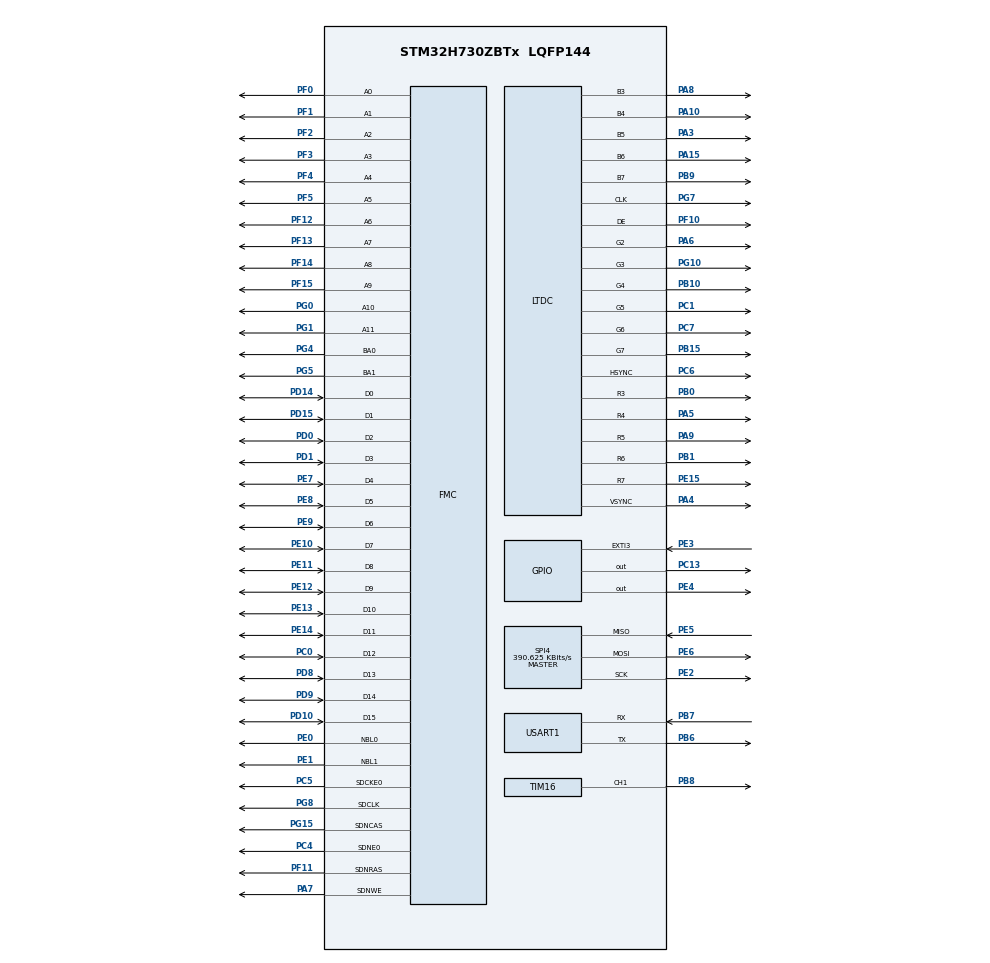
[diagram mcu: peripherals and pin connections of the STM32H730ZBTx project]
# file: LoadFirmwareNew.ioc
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CORTEX_M7.AccessPermission_S-Cortex_Memory_Protection_Unit_Region2_Settings_S=MPU_REGION_FULL_ACCESS
CORTEX_M7.AccessPermission_S-Cortex_Memory_Protection_Unit_Region3_Settings_S=MPU_REGION_FULL_ACCESS
CORTEX_M7.AccessPermission_S-Cortex_Memory_Protection_Unit_Region4_Settings_S=MPU_REGION_FULL_ACCESS
CORTEX_M7.AccessPermission_Spec=MPU_REGION_FULL_ACCESS
CORTEX_M7.BaseAddress_S-Cortex_Memory_Protection_Unit_Region2_Settings_S=0x38000000
CORTEX_M7.BaseAddress_S-Cortex_Memory_Protection_Unit_Region3_Settings_S=0x08000000
CORTEX_M7.BaseAddress_S-Cortex_Memory_Protection_Unit_Region4_Settings_S=0x90000000
CORTEX_M7.BaseAddress_Spec=0xC0000000
CORTEX_M7.CPU_DCache=Enabled
CORTEX_M7.CPU_ICache=Enabled
CORTEX_M7.DisableExec_S-Cortex_Memory_Protection_Unit_Region2_Settings_S=MPU_INSTRUCTION_ACCESS_DISABLE
CORTEX_M7.Enable_S-Cortex_Memory_Protection_Unit_Region1_Settings_S=__NULL
CORTEX_M7.Enable_S-Cortex_Memory_Protection_Unit_Region2_Settings_S=MPU_REGION_ENABLE
CORTEX_M7.Enable_S-Cortex_Memory_Protection_Unit_Region3_Settings_S=MPU_REGION_ENABLE
CORTEX_M7.Enable_S-Cortex_Memory_Protection_Unit_Region4_Settings_S=MPU_REGION_ENABLE
CORTEX_M7.IsBufferable_S-Cortex_Memory_Protection_Unit_Region2_Settings_S=MPU_ACCESS_BUFFERABLE
CORTEX_M7.IsBufferable_S-Cortex_Memory_Protection_Unit_Region4_Settings_S=MPU_ACCESS_NOT_BUFFERABLE
CORTEX_M7.IsBufferable_Spec=MPU_ACCESS_BUFFERABLE
CORTEX_M7.IsCacheable_S-Cortex_Memory_Protection_Unit_Region2_Settings_S=MPU_ACCESS_CACHEABLE
CORTEX_M7.IsCacheable_S-Cortex_Memory_Protection_Unit_Region3_Settings_S=MPU_ACCESS_CACHEABLE
CORTEX_M7.IsCacheable_S-Cortex_Memory_Protection_Unit_Region4_Settings_S=MPU_ACCESS_CACHEABLE
CORTEX_M7.IsCacheable_Spec=MPU_ACCESS_CACHEABLE
CORTEX_M7.IsShareable_S-Cortex_Memory_Protection_Unit_Region2_Settings_S=MPU_ACCESS_SHAREABLE
CORTEX_M7.IsShareable_S-Cortex_Memory_Protection_Unit_Region3_Settings_S=MPU_ACCESS_NOT_SHAREABLE
CORTEX_M7.IsShareable_S-Cortex_Memory_Protection_Unit_Region4_Settings_S=MPU_ACCESS_NOT_SHAREABLE
CORTEX_M7.IsShareable_Spec=MPU_ACCESS_SHAREABLE
CORTEX_M7.Size_S-Cortex_Memory_Protection_Unit_Region2_Settings_S=MPU_REGION_SIZE_16KB
CORTEX_M7.Size_S-Cortex_Memory_Protection_Unit_Region3_Settings_S=MPU_REGION_SIZE_128KB
CORTEX_M7.Size_S-Cortex_Memory_Protection_Unit_Region4_Settings_S=MPU_REGION_SIZE_16MB
CORTEX_M7.Size_Spec=MPU_REGION_SIZE_8MB
CORTEX_M7.SubRegionDisable_Spec=0x00
CORTEX_M7.default_mode_Activation=1
DMA2D.ColorMode=DMA2D_OUTPUT_RGB565
DMA2D.Mode=DMA2D_R2M
Dma.Request0=USART1_RX
Dma.Request1=USART1_TX
Dma.USART1_RX.0.Direction=DMA_PERIPH_TO_MEMORY
Dma.USART1_RX.0.EventEnable=DISABLE
Dma.USART1_RX.0.FIFOMode=DMA_FIFOMODE_DISABLE
Dma.USART1_RX.0.Instance=DMA1_Stream0
Dma.USART1_RX.0.MemDataAlignment=DMA_MDATAALIGN_BYTE
Dma.USART1_RX.0.MemInc=DMA_MINC_ENABLE
Dma.USART1_RX.0.Mode=DMA_CIRCULAR
Dma.USART1_RX.0.PeriphDataAlignment=DMA_PDATAALIGN_BYTE
Dma.USART1_RX.0.PeriphInc=DMA_PINC_DISABLE
Dma.USART1_RX.0.Polarity=HAL_DMAMUX_REQ_GEN_RISING
Dma.USART1_RX.0.Priority=DMA_PRIORITY_LOW
Dma.USART1_RX.0.RequestNumber=1
Dma.USART1_RX.0.SignalID=NONE
Dma.USART1_RX.0.SyncEnable=DISABLE
Dma.USART1_RX.0.SyncPolarity=HAL_DMAMUX_SYNC_NO_EVENT
Dma.USART1_RX.0.SyncRequestNumber=1
Dma.USART1_RX.0.SyncSignalID=NONE
Dma.USART1_TX.1.Direction=DMA_MEMORY_TO_PERIPH
Dma.USART1_TX.1.EventEnable=DISABLE
Dma.USART1_TX.1.FIFOMode=DMA_FIFOMODE_DISABLE
Dma.USART1_TX.1.Instance=DMA1_Stream1
Dma.USART1_TX.1.MemDataAlignment=DMA_MDATAALIGN_BYTE
Dma.USART1_TX.1.MemInc=DMA_MINC_ENABLE
Dma.USART1_TX.1.Mode=DMA_NORMAL
Dma.USART1_TX.1.PeriphDataAlignment=DMA_PDATAALIGN_BYTE
Dma.USART1_TX.1.PeriphInc=DMA_PINC_DISABLE
Dma.USART1_TX.1.Polarity=HAL_DMAMUX_REQ_GEN_RISING
Dma.USART1_TX.1.Priority=DMA_PRIORITY_LOW
Dma.USART1_TX.1.RequestNumber=1
Dma.USART1_TX.1.SignalID=NONE
Dma.USART1_TX.1.SyncEnable=DISABLE
Dma.USART1_TX.1.SyncPolarity=HAL_DMAMUX_SYNC_NO_EVENT
Dma.USART1_TX.1.SyncRequestNumber=1
Dma.USART1_TX.1.SyncSignalID=NONE
FMC.CASLatency1=FMC_SDRAM_CAS_LATENCY_2
FMC.ExitSelfRefreshDelay1=7
FMC.LoadToActiveDelay1=2
FMC.RCDDelay1=2
FMC.RPDelay1=2
FMC.RowCycleDelay1=6
FMC.SDClockPeriod1=FMC_SDRAM_CLOCK_PERIOD_2
FMC.SelfRefreshTime1=4
FMC.WriteRecoveryTime1=2
LTDC.ActiveW=800
LTDC.Alpha_L0=0xFF
LTDC.FBStartAdress_L0=0xC0000000
LTDC.FBStartAdress_L1=0xC0100000
LTDC.HBP=45
LTDC.HFP=212
LTDC.HSync=2
LTDC.ImageHeight_L0=480
LTDC.ImageHeight_L1=480
LTDC.ImageWidth_L0=800
LTDC.Layers=0
LTDC.PixelFormat_L0=LTDC_PIXEL_FORMAT_RGB565
LTDC.VBP=21
LTDC.VFP=21
LTDC.VSync=2
LTDC.WindowX1_L0=800
LTDC.WindowY1_L0=480
Mcu.Family=STM32H7
Mcu.Name=STM32H730ZBTx
Mcu.Package=LQFP144
NVIC.DMA1_Stream0_IRQn=true\:0\:0\:false\:false\:true\:false\:true\:true
NVIC.DMA1_Stream1_IRQn=true\:0\:0\:false\:false\:true\:false\:true\:true
NVIC.EXTI3_IRQn=true\:0\:0\:false\:false\:true\:true\:true\:true
NVIC.LTDC_ER_IRQn=true\:0\:0\:false\:false\:true\:true\:true\:true
NVIC.LTDC_IRQn=true\:0\:0\:false\:false\:true\:true\:true\:true
NVIC.PriorityGroup=NVIC_PRIORITYGROUP_4
NVIC.USART1_IRQn=true\:0\:0\:false\:false\:true\:true\:true\:true
PA10.GPIO_Speed=GPIO_SPEED_FREQ_VERY_HIGH
PA10.Mode=RGB565
PA10.Signal=LTDC_B4
PA15(JTDI).GPIO_Speed=GPIO_SPEED_FREQ_VERY_HIGH
PA15(JTDI).Mode=RGB565
PA15(JTDI).Signal=LTDC_B6
PA3.GPIO_Speed=GPIO_SPEED_FREQ_VERY_HIGH
PA3.Mode=RGB565
PA3.Signal=LTDC_B5
PA4.GPIO_Speed=GPIO_SPEED_FREQ_VERY_HIGH
PA4.Mode=RGB565
PA4.Signal=LTDC_VSYNC
PA5.GPIO_Speed=GPIO_SPEED_FREQ_VERY_HIGH
PA5.Mode=RGB565
PA5.Signal=LTDC_R4
PA6.GPIO_Speed=GPIO_SPEED_FREQ_VERY_HIGH
PA6.Mode=RGB565
PA6.Signal=LTDC_G2
PA7.Signal=FMC_SDNWE
PA8.GPIO_Speed=GPIO_SPEED_FREQ_VERY_HIGH
PA8.Mode=RGB565
PA8.Signal=LTDC_B3
PA9.GPIO_Speed=GPIO_SPEED_FREQ_VERY_HIGH
PA9.Mode=RGB565
PA9.Signal=LTDC_R5
PB0.GPIO_Speed=GPIO_SPEED_FREQ_VERY_HIGH
PB0.Mode=RGB565
PB0.Signal=LTDC_R3
PB1.GPIO_Speed=GPIO_SPEED_FREQ_VERY_HIGH
PB1.Mode=RGB565
PB1.Signal=LTDC_R6
PB10.GPIO_Speed=GPIO_SPEED_FREQ_VERY_HIGH
PB10.Mode=RGB565
PB10.Signal=LTDC_G4
PB15.GPIO_Speed=GPIO_SPEED_FREQ_VERY_HIGH
PB15.Mode=RGB565
PB15.Signal=LTDC_G7
PB6.Mode=Asynchronous
PB6.Signal=USART1_TX
PB7.Mode=Asynchronous
PB7.Signal=USART1_RX
PB8.Signal=S_TIM16_CH1
PB9.GPIO_Speed=GPIO_SPEED_FREQ_VERY_HIGH
PB9.Mode=RGB565
PB9.Signal=LTDC_B7
PC0.Signal=FMC_D12_DA12
PC1.GPIO_Speed=GPIO_SPEED_FREQ_VERY_HIGH
PC1.Mode=RGB565
PC1.Signal=LTDC_G5
PC13.Signal=GPIO_Output
PC4.Mode=SdramChipSelect1_1
PC4.Signal=FMC_SDNE0
PC5.Mode=SdramChipSelect1_1
PC5.Signal=FMC_SDCKE0
PC6.GPIO_Speed=GPIO_SPEED_FREQ_VERY_HIGH
PC6.Mode=RGB565
PC6.Signal=LTDC_HSYNC
PC7.GPIO_Speed=GPIO_SPEED_FREQ_VERY_HIGH
PC7.Mode=RGB565
PC7.Signal=LTDC_G6
PD0.Signal=FMC_D2_DA2
PD1.Signal=FMC_D3_DA3
PD10.Signal=FMC_D15_DA15
PD14.Signal=FMC_D0_DA0
PD15.Signal=FMC_D1_DA1
PD8.Signal=FMC_D13_DA13
PD9.Signal=FMC_D14_DA14
PE0.Signal=FMC_NBL0
PE1.Signal=FMC_NBL1
PE10.Signal=FMC_D7_DA7
PE11.Signal=FMC_D8_DA8
PE12.Signal=FMC_D9_DA9
PE13.Signal=FMC_D10_DA10
PE14.Signal=FMC_D11_DA11
PE15.GPIO_Speed=GPIO_SPEED_FREQ_VERY_HIGH
PE15.Mode=RGB565
PE15.Signal=LTDC_R7
PE2.GPIO_Speed=GPIO_SPEED_FREQ_LOW
PE2.Mode=Full_Duplex_Master
PE2.Signal=SPI4_SCK
PE3.GPIO_ModeDefaultEXTI=GPIO_MODE_IT_RISING
PE3.Signal=GPXTI3
PE4.GPIO_Speed=GPIO_SPEED_FREQ_LOW
PE4.Signal=GPIO_Output
PE5.GPIO_Speed=GPIO_SPEED_FREQ_LOW
PE5.Mode=Full_Duplex_Master
PE5.Signal=SPI4_MISO
PE6.GPIO_Speed=GPIO_SPEED_FREQ_LOW
PE6.Mode=Full_Duplex_Master
PE6.Signal=SPI4_MOSI
PE7.Signal=FMC_D4_DA4
PE8.Signal=FMC_D5_DA5
PE9.Signal=FMC_D6_DA6
PF0.Signal=FMC_A0
PF1.Signal=FMC_A1
PF10.GPIO_Speed=GPIO_SPEED_FREQ_VERY_HIGH
PF10.Mode=RGB565
PF10.Signal=LTDC_DE
PF11.Signal=FMC_SDNRAS
PF12.Signal=FMC_A6
PF13.Signal=FMC_A7
PF14.Signal=FMC_A8
PF15.Signal=FMC_A9
PF2.Signal=FMC_A2
PF3.Signal=FMC_A3
PF4.Signal=FMC_A4
PF5.Signal=FMC_A5
PG0.Signal=FMC_A10
PG1.Signal=FMC_A11
PG10.GPIO_Speed=GPIO_SPEED_FREQ_VERY_HIGH
PG10.Mode=RGB565
PG10.Signal=LTDC_G3
PG15.Signal=FMC_SDNCAS
PG4.Signal=FMC_A14_BA0
PG5.Signal=FMC_A15_BA1
PG7.GPIO_Speed=GPIO_SPEED_FREQ_VERY_HIGH
PG7.Mode=RGB565
PG7.Signal=LTDC_CLK
PG8.Signal=FMC_SDCLK
PH0-OSC_IN.Mode=HSE-External-Oscillator
PH0-OSC_IN.Signal=RCC_OSC_IN
PH1-OSC_OUT.Mode=HSE-External-Oscillator
PH1-OSC_OUT.Signal=RCC_OSC_OUT
ProjectManager.HeapSize=0x200
ProjectManager.StackSize=0x400
ProjectManager.TargetToolchain=STM32CubeIDE
RCC.ADCFreq_Value=200000000
RCC.APB1Freq_Value=100000000
RCC.APB2Freq_Value=100000000
RCC.APB3Freq_Value=100000000
RCC.APB4Freq_Value=100000000
RCC.CortexFreq_Value=400000000
RCC.D1PPRE=RCC_APB3_DIV2
RCC.D2PPRE1=RCC_APB1_DIV2
RCC.D2PPRE2=RCC_APB2_DIV2
RCC.D3PPRE=RCC_APB4_DIV2
RCC.DIVM1=2
RCC.DIVM2=10
RCC.DIVM3=1
RCC.DIVN1=32
RCC.DIVN2=160
RCC.DIVN3=4
RCC.DIVP1=1
RCC.DIVQ1=1
RCC.DIVQ2=1
RCC.DIVQ3=1
RCC.DIVR3=5
RCC.HCLKFreq_Value=200000000
RCC.HPRE=RCC_HCLK_DIV2
RCC.PLL3FRACN=0
RCC.PLLFRACN=0
RCC.PLLSourceVirtual=RCC_PLLSOURCE_HSE
RCC.SYSCLKFreq_VALUE=400000000
RCC.SYSCLKSource=RCC_SYSCLKSOURCE_PLLCLK
RCC.USBFreq_Value=400000000
SH.FMC_A0.0=FMC_A0,12b-sda1
SH.FMC_A1.0=FMC_A1,12b-sda1
SH.FMC_A10.0=FMC_A10,12b-sda1
SH.FMC_A11.0=FMC_A11,12b-sda1
SH.FMC_A14_BA0.0=FMC_BA0,FourSdramBanks1
SH.FMC_A15_BA1.0=FMC_BA1,FourSdramBanks1
SH.FMC_A2.0=FMC_A2,12b-sda1
SH.FMC_A3.0=FMC_A3,12b-sda1
SH.FMC_A4.0=FMC_A4,12b-sda1
SH.FMC_A5.0=FMC_A5,12b-sda1
SH.FMC_A6.0=FMC_A6,12b-sda1
SH.FMC_A7.0=FMC_A7,12b-sda1
SH.FMC_A8.0=FMC_A8,12b-sda1
SH.FMC_A9.0=FMC_A9,12b-sda1
SH.FMC_D0_DA0.0=FMC_D0,sd-16b-d1
SH.FMC_D10_DA10.0=FMC_D10,sd-16b-d1
SH.FMC_D11_DA11.0=FMC_D11,sd-16b-d1
SH.FMC_D12_DA12.0=FMC_D12,sd-16b-d1
SH.FMC_D13_DA13.0=FMC_D13,sd-16b-d1
SH.FMC_D14_DA14.0=FMC_D14,sd-16b-d1
SH.FMC_D15_DA15.0=FMC_D15,sd-16b-d1
SH.FMC_D1_DA1.0=FMC_D1,sd-16b-d1
SH.FMC_D2_DA2.0=FMC_D2,sd-16b-d1
SH.FMC_D3_DA3.0=FMC_D3,sd-16b-d1
SH.FMC_D4_DA4.0=FMC_D4,sd-16b-d1
SH.FMC_D5_DA5.0=FMC_D5,sd-16b-d1
SH.FMC_D6_DA6.0=FMC_D6,sd-16b-d1
SH.FMC_D7_DA7.0=FMC_D7,sd-16b-d1
SH.FMC_D8_DA8.0=FMC_D8,sd-16b-d1
SH.FMC_D9_DA9.0=FMC_D9,sd-16b-d1
SH.FMC_NBL0.0=FMC_NBL0,Sd2ByteEnable1
SH.FMC_NBL1.0=FMC_NBL1,Sd2ByteEnable1
SH.FMC_SDCLK.0=FMC_SDCLK,12b-sda1
SH.FMC_SDNCAS.0=FMC_SDNCAS,12b-sda1
SH.FMC_SDNRAS.0=FMC_SDNRAS,12b-sda1
SH.FMC_SDNWE.0=FMC_SDNWE,12b-sda1
SH.S_TIM16_CH1.0=TIM16_CH1,PWM Generation1 CH1
SPI4.BaudRatePrescaler=SPI_BAUDRATEPRESCALER_256
SPI4.CalculateBaudRate=390.625 KBits/s
SPI4.DataSize=SPI_DATASIZE_8BIT
SPI4.Direction=SPI_DIRECTION_2LINES
SPI4.Mode=SPI_MODE_MASTER
SPI4.VirtualType=VM_MASTER
STMicroelectronics.X-CUBE-TOUCHGFX.4.24.1.ApplicationCcGraphicsJjApplication=TouchGFXOoGenerator
STMicroelectronics.X-CUBE-TOUCHGFX.4.24.1.tgfx_address1=0xC0000000
STMicroelectronics.X-CUBE-TOUCHGFX.4.24.1.tgfx_address2=0xC0100000
STMicroelectronics.X-CUBE-TOUCHGFX.4.24.1.tgfx_buffering_strategy=Double
STMicroelectronics.X-CUBE-TOUCHGFX.4.24.1.tgfx_display_interface=disp_ltdc
STMicroelectronics.X-CUBE-TOUCHGFX.4.24.1.tgfx_hardware_accelerator=dma_2d
STMicroelectronics.X-CUBE-TOUCHGFX.4.24.1.tgfx_location=By Address
STMicroelectronics.X-CUBE-TOUCHGFX.4.24.1.tgfx_vector_rendering=Software
STMicroelectronics.X-CUBE-TOUCHGFX.4.24.1.tgfx_video=Software
STMicroelectronics.X-CUBE-TOUCHGFX.4.24.1.tgfx_video_height=480
STMicroelectronics.X-CUBE-TOUCHGFX.4.24.1.tgfx_video_width=800
STMicroelectronics.X-CUBE-TOUCHGFX.4.24.1.tgfx_vsync=vsync_ltdc
STMicroelectronics.X-CUBE-TOUCHGFX.4.24.1_IsPackSelfContextualization=true
TIM16.Channel=TIM_CHANNEL_1
TIM16.Period=100
TIM16.Prescaler=10000
TIM16.Pulse=100
TIM6.Period=50000 - 1
TIM6.Prescaler=55000 - 1
USART1.VirtualMode-Asynchronous=VM_ASYNC
VP_CRC_VS_CRC.Mode=CRC_Activate
VP_DMA2D_VS_DMA2D.Mode=DMA2D_Activate
VP_LIBJPEG_VS_JPEGLIB.Mode=Enabled
VP_MEMORYMAP_VS_MEMORYMAP.Mode=CurAppReg
VP_STMicroelectronics.X-CUBE-TOUCHGFX_VS_GraphicsJjApplication_4.24.1.Mode=GraphicsJjApplication
VP_TIM16_VS_ClockSourceINT.Mode=Enable_Timer
VP_TIM6_VS_ClockSourceINT.Mode=Enable_Timer
board=custom

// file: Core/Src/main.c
/* USER CODE BEGIN Header */
/**
  ******************************************************************************
  * @file           : main.c
  * @brief          : Main program body
  ******************************************************************************
  * @attention
  *
  * Copyright (c) 2024 STMicroelectronics.
  * All rights reserved.
  *
  * This software is licensed under terms that can be found in the LICENSE file
  * in the root directory of this software component.
  * If no LICENSE file comes with this software, it is provided AS-IS.
  *
  ******************************************************************************
  */
/* USER CODE END Header */
#include "main.h"
#include "crc.h"
#include "dma.h"
#include "dma2d.h"
#include "libjpeg.h"
#include "ltdc.h"
#include "memorymap.h"
#include "spi.h"
#include "tim.h"
#include "usart.h"
#include "gpio.h"
#include "fmc.h"
#include "app_touchgfx.h"

void SystemClock_Config(void);
static void MPU_Config(void);

int main(void)
{

  /* MPU Configuration--------------------------------------------------------*/
  MPU_Config();

  /* Enable the CPU Cache */

  /* Enable I-Cache---------------------------------------------------------*/
  SCB_EnableICache();

  /* Enable D-Cache---------------------------------------------------------*/
  SCB_EnableDCache();

  /* MCU Configuration--------------------------------------------------------*/

  /* Reset of all peripherals, Initializes the Flash interface and the Systick. */
  HAL_Init();

  /* Configure the system clock */
  SystemClock_Config();

  /* Initialize all configured peripherals */
  MX_GPIO_Init();
  MX_DMA_Init();
  MX_FMC_Init();
  MX_TIM6_Init();
  MX_TIM16_Init();
  MX_USART1_UART_Init();
  MX_DMA2D_Init();
  MX_CRC_Init();
  MX_LTDC_Init();
  MX_SPI4_Init();
  MX_LIBJPEG_Init();
  MX_TouchGFX_Init();

  /* Infinite loop */
  while (1)
  {

  MX_TouchGFX_Process();
    /* USER CODE BEGIN 3 */
		HAL_GPIO_WritePin(GPIOC, GPIO_PIN_13, GPIO_PIN_SET);
		HAL_Delay(500);
		HAL_GPIO_WritePin(GPIOC, GPIO_PIN_13, GPIO_PIN_RESET);
		HAL_Delay(500);
  }
  /* USER CODE END 3 */
}

void SystemClock_Config(void)
{
  RCC_OscInitTypeDef RCC_OscInitStruct = {0};
  RCC_ClkInitTypeDef RCC_ClkInitStruct = {0};

  /** Supply configuration update enable
  */
  HAL_PWREx_ConfigSupply(PWR_LDO_SUPPLY);

  /** Configure the main internal regulator output voltage
  */
  __HAL_PWR_VOLTAGESCALING_CONFIG(PWR_REGULATOR_VOLTAGE_SCALE1);

  while(!__HAL_PWR_GET_FLAG(PWR_FLAG_VOSRDY)) {}

  /** Initializes the RCC Oscillators according to the specified parameters
  * in the RCC_OscInitTypeDef structure.
  */
  RCC_OscInitStruct.OscillatorType = RCC_OSCILLATORTYPE_HSE;
  RCC_OscInitStruct.HSEState = RCC_HSE_ON;
  RCC_OscInitStruct.PLL.PLLState = RCC_PLL_ON;
  RCC_OscInitStruct.PLL.PLLSource = RCC_PLLSOURCE_HSE;
  RCC_OscInitStruct.PLL.PLLM = 2;
  RCC_OscInitStruct.PLL.PLLN = 32;
  RCC_OscInitStruct.PLL.PLLP = 1;
  RCC_OscInitStruct.PLL.PLLQ = 1;
  RCC_OscInitStruct.PLL.PLLR = 2;
  RCC_OscInitStruct.PLL.PLLRGE = RCC_PLL1VCIRANGE_3;
  RCC_OscInitStruct.PLL.PLLVCOSEL = RCC_PLL1VCOWIDE;
  RCC_OscInitStruct.PLL.PLLFRACN = 0;
  if (HAL_RCC_OscConfig(&RCC_OscInitStruct) != HAL_OK)
  {
    Error_Handler();
  }

  /** Initializes the CPU, AHB and APB buses clocks
  */
  RCC_ClkInitStruct.ClockType = RCC_CLOCKTYPE_HCLK|RCC_CLOCKTYPE_SYSCLK
                              |RCC_CLOCKTYPE_PCLK1|RCC_CLOCKTYPE_PCLK2
                              |RCC_CLOCKTYPE_D3PCLK1|RCC_CLOCKTYPE_D1PCLK1;
  RCC_ClkInitStruct.SYSCLKSource = RCC_SYSCLKSOURCE_PLLCLK;
  RCC_ClkInitStruct.SYSCLKDivider = RCC_SYSCLK_DIV1;
  RCC_ClkInitStruct.AHBCLKDivider = RCC_HCLK_DIV2;
  RCC_ClkInitStruct.APB3CLKDivider = RCC_APB3_DIV2;
  RCC_ClkInitStruct.APB1CLKDivider = RCC_APB1_DIV2;
  RCC_ClkInitStruct.APB2CLKDivider = RCC_APB2_DIV2;
  RCC_ClkInitStruct.APB4CLKDivider = RCC_APB4_DIV2;

  if (HAL_RCC_ClockConfig(&RCC_ClkInitStruct, FLASH_LATENCY_2) != HAL_OK)
  {
    Error_Handler();
  }
}

 /* MPU Configuration */

void MPU_Config(void)
{
  MPU_Region_InitTypeDef MPU_InitStruct = {0};

  /* Disables the MPU */
  HAL_MPU_Disable();

  /** Initializes and configures the Region and the memory to be protected
  */
  MPU_InitStruct.Enable = MPU_REGION_ENABLE;
  MPU_InitStruct.Number = MPU_REGION_NUMBER0;
  MPU_InitStruct.BaseAddress = 0xC0000000;
  MPU_InitStruct.Size = MPU_REGION_SIZE_8MB;
  MPU_InitStruct.SubRegionDisable = 0x00;
  MPU_InitStruct.TypeExtField = MPU_TEX_LEVEL0;
  MPU_InitStruct.AccessPermission = MPU_REGION_FULL_ACCESS;
  MPU_InitStruct.DisableExec = MPU_INSTRUCTION_ACCESS_DISABLE;
  MPU_InitStruct.IsShareable = MPU_ACCESS_SHAREABLE;
  MPU_InitStruct.IsCacheable = MPU_ACCESS_CACHEABLE;
  MPU_InitStruct.IsBufferable = MPU_ACCESS_BUFFERABLE;

  HAL_MPU_ConfigRegion(&MPU_InitStruct);

  /** Initializes and configures the Region and the memory to be protected
  */
  MPU_InitStruct.Number = MPU_REGION_NUMBER2;
  MPU_InitStruct.BaseAddress = 0x38000000;
  MPU_InitStruct.Size = MPU_REGION_SIZE_16KB;
  MPU_InitStruct.SubRegionDisable = 0x0;

  HAL_MPU_ConfigRegion(&MPU_InitStruct);

  /** Initializes and configures the Region and the memory to be protected
  */
  MPU_InitStruct.Number = MPU_REGION_NUMBER3;
  MPU_InitStruct.BaseAddress = 0x08000000;
  MPU_InitStruct.Size = MPU_REGION_SIZE_128KB;
  MPU_InitStruct.DisableExec = MPU_INSTRUCTION_ACCESS_ENABLE;
  MPU_InitStruct.IsShareable = MPU_ACCESS_NOT_SHAREABLE;
  MPU_InitStruct.IsBufferable = MPU_ACCESS_NOT_BUFFERABLE;

  HAL_MPU_ConfigRegion(&MPU_InitStruct);

  /** Initializes and configures the Region and the memory to be protected
  */
  MPU_InitStruct.Number = MPU_REGION_NUMBER4;
  MPU_InitStruct.BaseAddress = 0x90000000;
  MPU_InitStruct.Size = MPU_REGION_SIZE_16MB;

  HAL_MPU_ConfigRegion(&MPU_InitStruct);
  /* Enables the MPU */
  HAL_MPU_Enable(MPU_PRIVILEGED_DEFAULT);

}

void Error_Handler(void)
{
  __disable_irq();
  while (1)
  {
  }
}
